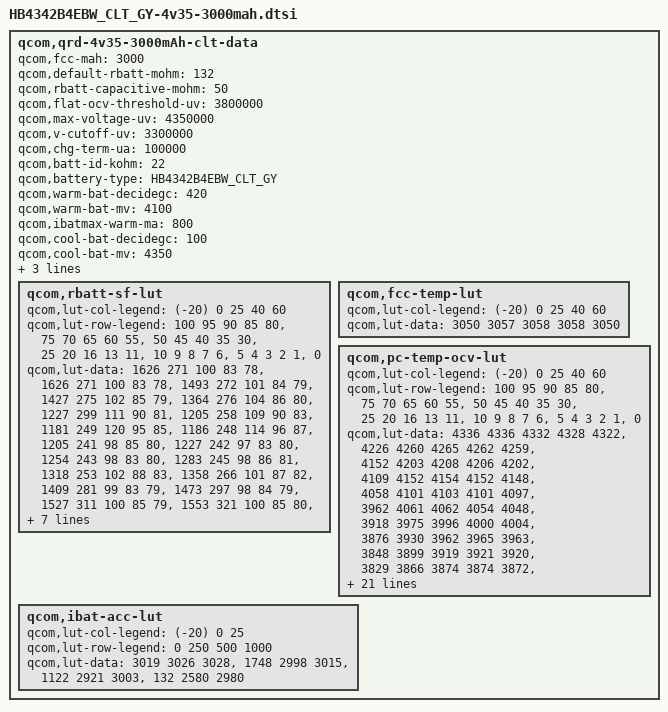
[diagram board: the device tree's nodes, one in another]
/* Copyright (c) 2013, The Linux Foundation. All rights reserved.
 *
 * This program is free software; you can redistribute it and/or modify
 * it under the terms of the GNU General Public License version 2 and
 * only version 2 as published by the Free Software Foundation.
 *
 * This program is distributed in the hope that it will be useful,
 * but WITHOUT ANY WARRANTY; without even the implied warranty of
 * MERCHANTABILITY or FITNESS FOR A PARTICULAR PURPOSE.  See the
 * GNU General Public License for more details.
 */

qcom,qrd-4v35-3000mAh-clt-data {
	qcom,fcc-mah = <3000>;
	qcom,default-rbatt-mohm = <132>;
	qcom,rbatt-capacitive-mohm = <50>;
	qcom,flat-ocv-threshold-uv = <3800000>;
	qcom,max-voltage-uv = <4350000>;
	qcom,v-cutoff-uv = <3300000>;
	qcom,chg-term-ua = <100000>;
	qcom,batt-id-kohm = <22>;
	qcom,battery-type = "HB4342B4EBW_CLT_GY";

	qcom,warm-bat-decidegc = <420>;
	qcom,warm-bat-mv = <4100>;
	qcom,ibatmax-warm-ma = <800>;

	qcom,cool-bat-decidegc = <100>;
	qcom,cool-bat-mv = <4350>;
	qcom,ibatmax-cool-ma = <600>;

	qcom,hot-bat-decidegc = <520>;
	qcom,cold-bat-decidegc = <0>;
	qcom,rbatt-sf-lut {
		qcom,lut-col-legend = <(-20) 0 25 40 60>;
		qcom,lut-row-legend = <100 95 90 85 80>,
				<75 70 65 60 55>,
				<50 45 40 35 30>,
				<25 20 16 13 11>,
				<10 9 8 7 6>,
				<5 4 3 2 1>,
				<0>;
		qcom,lut-data = <1626 271 100 83 78>,
				<1626 271 100 83 78>,
				<1493 272 101 84 79>,
				<1427 275 102 85 79>,
				<1364 276 104 86 80>,
				<1227 299 111 90 81>,
				<1205 258 109 90 83>,
				<1181 249 120 95 85>,
				<1186 248 114 96 87>,
				<1205 241 98 85 80>,
				<1227 242 97 83 80>,
				<1254 243 98 83 80>,
				<1283 245 98 86 81>,
				<1318 253 102 88 83>,
				<1358 266 101 87 82>,
				<1409 281 99 83 79>,
				<1473 297 98 84 79>,
				<1527 311 100 85 79>,
				<1553 321 100 85 80>,
				<1486 314 98 85 80>,
				<1518 323 100 85 82>,
				<1553 333 102 86 82>,
				<1633 347 104 88 83>,
				<1764 362 105 89 85>,
				<1948 374 105 88 83>,
				<2183 380 104 86 82>,
				<2505 397 105 86 83>,
				<2973 427 108 90 83>,
				<3794 475 114 93 87>,
				<8089 1217 180 138 117>,
				<92991 44342 40458 37503 25257>;
	};

	qcom,fcc-temp-lut {
		qcom,lut-col-legend = <(-20) 0 25 40 60>;
		qcom,lut-data = <3050 3057 3058 3058 3050>;
	};

	qcom,pc-temp-ocv-lut {
		qcom,lut-col-legend = <(-20) 0 25 40 60>;
		qcom,lut-row-legend = <100 95 90 85 80>,
				<75 70 65 60 55>,
				<50 45 40 35 30>,
				<25 20 16 13 11>,
				<10 9 8 7 6>,
				<5 4 3 2 1>,
				<0>;
		qcom,lut-data = <4336 4336 4332 4328 4322>,
				<4226 4260 4265 4262 4259>,
				<4152 4203 4208 4206 4202>,
				<4109 4152 4154 4152 4148>,
				<4058 4101 4103 4101 4097>,
				<3962 4061 4062 4054 4048>,
				<3918 3975 3996 4000 4004>,
				<3876 3930 3962 3965 3963>,
				<3848 3899 3919 3921 3920>,
				<3829 3866 3874 3874 3872>,
				<3812 3838 3844 3844 3844>,
				<3798 3814 3822 3822 3820>,
				<3783 3796 3803 3803 3801>,
				<3769 3782 3787 3787 3784>,
				<3754 3771 3772 3768 3763>,
				<3737 3758 3754 3746 3734>,
				<3719 3740 3736 3726 3712>,
				<3701 3720 3717 3708 3694>,
				<3684 3705 3698 3688 3676>,
				<3669 3698 3690 3682 3670>,
				<3659 3694 3689 3681 3669>,
				<3648 3691 3687 3680 3668>,
				<3634 3688 3684 3677 3664>,
				<3616 3682 3680 3672 3658>,
				<3594 3669 3668 3658 3638>,
				<3566 3640 3636 3625 3602>,
				<3528 3598 3590 3580 3554>,
				<3476 3541 3529 3516 3491>,
				<3400 3456 3446 3432 3404>,
				<3270 3324 3312 3298 3268>,
				<3000 3000 3000 3000 3000>;
	};
	qcom,ibat-acc-lut {
		qcom,lut-col-legend = <(-20) 0 25>;
		qcom,lut-row-legend = <0 250 500 1000>;
		qcom,lut-data = <3019 3026 3028>,
				<1748 2998 3015>,
				<1122 2921 3003>,
				<132 2580 2980>;
};
};
